# RN831X_RN861X_MCU register map
File version: v0.0.1
CPU: RN831X_RN861X_MCU r1p0, little endian, MPU, no FPU
Registers are 32-bit, read-write, reset 0x0 unless marked. A register's access mark holds for its fields unless they carry their own. Offsets are from the block's base; [hi:lo] are bit positions.

## M2M_CORE0 — M2M module
Base 0x20078000
Same registers: M2M_CORE1 0xA0078000
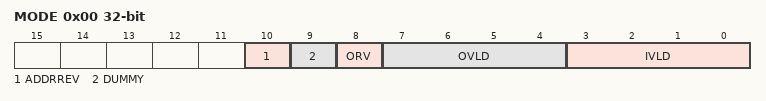
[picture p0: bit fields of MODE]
0x00 MODE — M2M Mode Register.
  [10] ADDRREV — Reverse data by address.
  [9] DUMMY — Enable set dummy value.
  [8] ORV — Reverse output data in byte.
  [7:4] OVLD — Set output data valid in byte.
  [3:0] IVLD — Set input data valid in byte.
0x04 CTRL — M2M Control Register.
  [0] EN — Enable M2M running
0x08 DUMMY — M2M invalid address Dummy value Register.
  [31:0] VAL — Set dummy value
0x0C SADDR — M2M Source Data Address Register.
  [16:0] ADDR — Set source data address
0x10 DADDR — M2M Destination Data Address Register.
  [16:0] ADDR — Set destination data address
0x14 ILEN — M2M Source Data Length Register.
  [16:0] LEN — Set data length
0x18 IE — M2M Interrupt Enable Register.
  [0] DONE — Enable M2M interrupt
0x1C IF — M2M Interrupt Flags Register.
  [0] DONE — Check M2M interrupt flag

## MADC_CORE0 — ADC
Base 0x200B8000
Same registers: MADC_CORE1 0xA00B8000
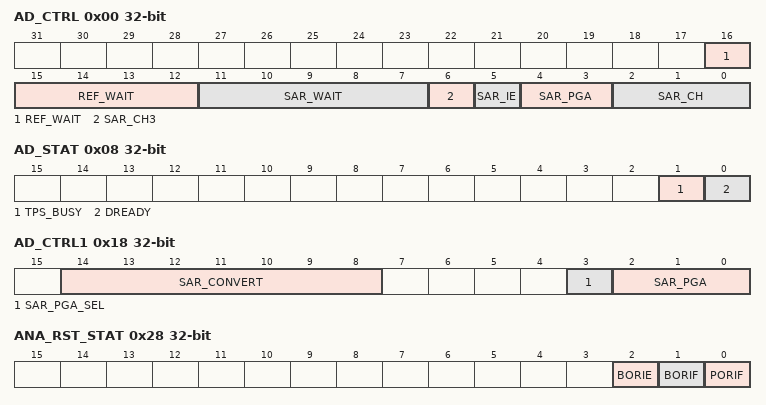
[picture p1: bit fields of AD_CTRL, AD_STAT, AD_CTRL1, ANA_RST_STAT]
0x00 AD_CTRL access not given — SAR ADC control register
  [16:12] REF_WAIT — set voltage reference duration config bits((REF_WAIT+1)*30.5us) between REF enable and ADC enable
  [11:7] SAR_WAIT — set SAR ADC duration config bits((SAR_WAIT+1)*30.5us) between enable and sample
  [6] SAR_CH3 — SAR ADC channel selection bits(part2)
  [5] SAR_IE — SAR ADC interrupt enable bit
    0=DIS (do not generate interrupt request on SAR event); 1=EN (generate interrupt request on SAR event)
  [4:3] SAR_PGA — SAR ADC PGA selection bits(old configuration used for compatibility)
  [2:0] SAR_CH — SAR ADC channel selection bits(part1)
0x04 AD_START access not given — SAR ADC start register
  [0] AD_START — SAR ADC start control bit, =1 start sar-measure once
0x08 AD_STAT access per field — SAR ADC status register
  [1] TPS_BUSY ro — automatic temperature measurement busy flag
    0=IDLE (no outstanding automatic temperature measurement); 1=BUSY (pending automatic temperature measurement)
  [0] DREADY rw write-1-clears — SAR ADC data ready/pending flag
    0=PEND (SAR ADC data pending flag); 1=READY (SAR ADC data ready flag)
0x0C AD_DATA ro — SAR ADC data register
  [9:0] AD_DATA — SAR ADC result data bits
0x18 AD_CTRL1 access not given — SAR ADC control register No.1
  [14:8] SAR_CONVERT — SAR ADC simple to DOUT wait time config bits
  [3] SAR_PGA_SEL — SAR ADC PGA selection bits
    0=CTRL_PGA (select AD_CTRL[4:3] PGA as PGA); 1=CTRL1_PGA (select AD_CTRL1[2:0] PGA as PGA)
  [2:0] SAR_PGA — SAR ADC PGA config bits
    0=0P5 (PGA select as 0.5); 1=1P0 (PGA select as 1.0); 2=1P5 (PGA select as 1.5); 3=2P0 (PGA select as 2.0); 4=0P25 (PGA select as 0.25)
0x1C AD_DATA2 ro — SAR ADC data register 2
  [11:0] AD_DATA2 — SAR ADC 12 bit result data bits
0x20 AD_CTRL3 access not given — SAR ADC control register No.3
  [7:0] ACC_CNT — SAR ADC output data accumulation count configuration(for AD_DATA3)
0x24 AD_DATA3 ro — SAR ADC data register 3
  [15:0] AD_DATA3 — SAR ADC 16 bit result data bits
0x28 ANA_RST_STAT — ANA reset state register
  [2] BORIE — BOR reset interrupt enable bit
  [1] BORIF write-1-clears — BOR reset interrupt flag
  [0] PORIF write-1-clears — POR reset interrupt flag(POR reset interrupt is a non-maskable interrupt)
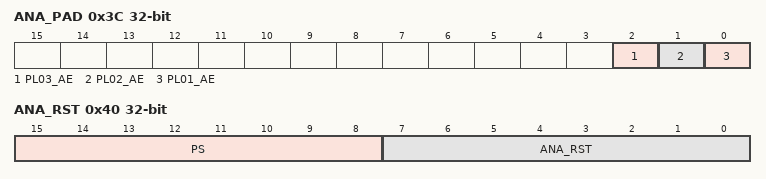
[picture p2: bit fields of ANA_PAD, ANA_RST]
0x3C ANA_PAD access not given
  [all] fields
    0=DIS (disable analog input); 1=EN (enable analog input)
  [2] PL03_AE — Enable bit for SAR AIN7 analog input
  [1] PL02_AE — Enable bit for SAR AIN6 analog input
  [0] PL01_AE — Enable bit for SAR AIN5 analog input
0x40 ANA_RST access not given — VBAT soft reset register
  [15:8] PS — password cfg bits of ANA_RST
    165=PS (password of ANA_RST); 0=DIS (disable [7:0]write)
  [7:0] ANA_RST — Reset all resetable register of VBAT
    168=RST (Reset all resetable register of VBAT); 0=NUL (Do not reset)
